# M0A21 register map
File version: 1.0
Registers are 32-bit, read-write, reset 0x0 unless marked. A register's access mark holds for its fields unless they carry their own. Offsets are from the block's base; [hi:lo] are bit positions; {n}, {i} and the like mark numbered series; 'fields as' and 'values as' point back to an identical list.

## ACMP01 — ACMP Register Map
Base 0x40045000
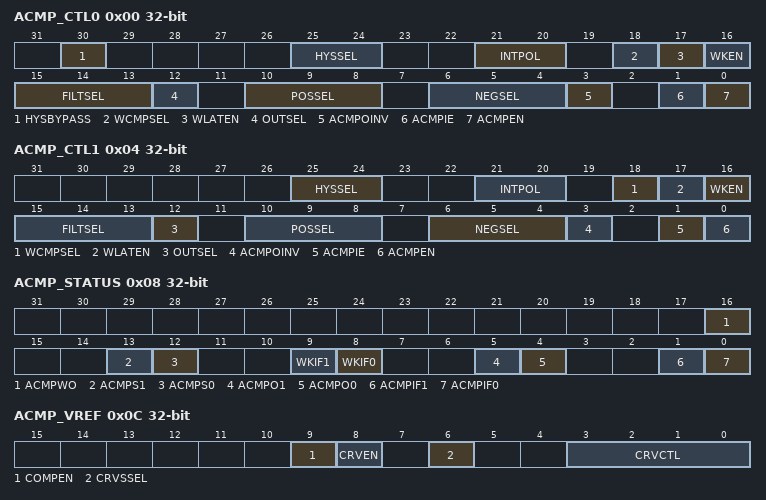
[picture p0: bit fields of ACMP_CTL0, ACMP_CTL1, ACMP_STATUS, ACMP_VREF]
0x00 ACMP_CTL0 — Analog Comparator 0 Control Register
  [30] HYSBYPASS — Hysteresis Adjust Function Selection
    0=Enable adjust function; 1=Bypass adjust function
  [25:24] HYSSEL — Hysteresis Mode Selection
    0=Hysteresis is 0mV; 3=Hysteresis is 30mV
  [21:20] INTPOL — Interrupt Condition Polarity Selection. ACMPIF0 will be set to 1 when comparator output edge condition is detected.
    0=Rising edge or falling edge; 1=Rising edge; 2=Falling edge
  [18] WCMPSEL — Window Compare Mode Selection
    0=Window Compare Mode Disabled; 1=Window Compare Mode Selected
  [17] WLATEN — Window Latch Mode Enable Bit
    0=Window Latch Mode Disabled; 1=Window Latch Mode Enabled
  [16] WKEN — Power-down Wake-up Enable Bit
    0=Wake-up function Disabled; 1=Wake-up function Enabled
  [15:13] FILTSEL — Comparator Output Filter Count Selection
    0=Filter function is Disabled; 1=ACMP0 output is sampled 1 consecutive PCLK; 2=ACMP0 output is sampled 2 consecutive PCLKs; 3=ACMP0 output is sampled 4 consecutive PCLKs; 4=ACMP0 output is sampled 8 consecutive PCLKs; 5=ACMP0 output is sampled 16 consecutive PCLKs; 6=ACMP0 output is sampled 32 consecutive PCLKs; 7=ACMP0 output is sampled 64 consecutive PCLKs
  [12] OUTSEL — Comparator Output Select
    0=Comparator 0 output to ACMP0_O pin is unfiltered comparator output; 1=Comparator 0 output to ACMP0_O pin is from filter output
  [10:8] POSSEL — Comparator Positive Input Selection
    0=All positive input disabled; 1=Input from ACMP0_P0; 2=Comparator Reference Voltage (CRV); 3=DAC0 output
  [6:4] NEGSEL — Comparator Negative Input Selection
    0=All negative input disbaled; {v}=ACMP0_N{v-1} (v=1..4); 5=Comparator Reference Voltage (CRV)
  [3] ACMPOINV — Comparator Output Inverse
    0=Comparator 0 output inverse Disabled; 1=Comparator 0 output inverse Enabled
  [1] ACMPIE — Comparator Interrupt Enable Bit
    0=Comparator 0 interrupt Disabled; 1=Comparator 0 interrupt Enabled. If WKEN (ACMP_CTL0[16]) is set to 1, the wake-up interrupt function will be enabled as well
  [0] ACMPEN — Comparator Enable Bit
    0=Comparator 0 Disabled; 1=Comparator 0 Enabled
0x04 ACMP_CTL1 — Analog Comparator 1 Control Register
  [25:24] HYSSEL — Hysteresis Mode Selection
    0=Hysteresis is 0mV; 3=Hysteresis is 30mV
  [21:20] INTPOL — Interrupt Condition Polarity Selection. ACMPIF0 will be set to 1 when comparator output edge condition is detected.
    0=Rising edge or falling edge; 1=Rising edge; 2=Falling edge
  [18] WCMPSEL — Window Compare Mode Selection
    values as ACMP_CTL0.WCMPSEL
  [17] WLATEN — Window Latch Mode Enable Bit
    0=Window Latch Mode Disabled; 1=Window Latch Mode Enabled
  [16] WKEN — Power-down Wakeup Enable Bit
    0=Wake-up function Disabled; 1=Wake-up function Enabled
  [15:13] FILTSEL — Comparator Output Filter Count Selection
    0=Filter function is Disabled; 1=ACMP1 output is sampled 1 consecutive PCLK; 2=ACMP1 output is sampled 2 consecutive PCLKs; 3=ACMP1 output is sampled 4 consecutive PCLKs; 4=ACMP1 output is sampled 8 consecutive PCLKs; 5=ACMP1 output is sampled 16 consecutive PCLKs; 6=ACMP1 output is sampled 32 consecutive PCLKs; 7=ACMP1 output is sampled 64 consecutive PCLKs
  [12] OUTSEL — Comparator Output Select
    0=Comparator 1 output to ACMP1_O pin is unfiltered comparator output; 1=Comparator 1 output to ACMP1_O pin is from filter output
  [10:8] POSSEL — Comparator Positive Input Selection
    0=All positive input disabled; 1=Input from ACMP1_P0; 2=Comparator Reference Voltage (CRV); 3=DAC0 output
  [6:4] NEGSEL — Comparator Negative Input Selection
    0=All negative input disbaled; {v}=ACMP1_N{v-1} (v=1..4); 5=Comparator Reference Voltage (CRV)
  [3] ACMPOINV — Comparator Output Inverse Control
    0=Comparator 1 output inverse Disabled; 1=Comparator 1 output inverse Enabled
  [1] ACMPIE — Comparator Interrupt Enable Bit
    0=Comparator 1 interrupt Disabled; 1=Comparator 1 interrupt Enabled. If WKEN (ACMP_CTL1[16]) is set to 1, the wake-up interrupt function will be enabled as well
  [0] ACMPEN — Comparator Enable Bit
    0=Comparator 1 Disabled; 1=Comparator 1 Enabled
0x08 ACMP_STATUS — Analog Comparator Status Register
  [16] ACMPWO — Comparator Window Output. This bit shows the output status of window compare mode
    0=The positive input voltage is outside the window; 1=The positive input voltage is in the window
  [13] ACMPS1 — Comparator 1 Status. Synchronized to the PCLK to allow reading by software. Cleared when the comparator 1 is disabled, i.e. ACMPEN (ACMP_CTL1[0]) is cleared to 0.
  [12] ACMPS0 — Comparator 0 Status. Synchronized to the PCLK to allow reading by software. Cleared when the comparator 0 is disabled, i.e. ACMPEN (ACMP_CTL0[0]) is cleared to 0.
  [9] WKIF1 — Comparator 1 Power-down Wake-up Interrupt Flag. This bit will be set to 1 when ACMP1 wake-up interrupt event occurs. Note: Write 1 to clear this bit to 0.
    0=No power-down wake-up occurred; 1=Power-down wake-up occurred
  [8] WKIF0 — Comparator 0 Power-down Wake-up Interrupt Flag. This bit will be set to 1 when ACMP0 wake-up interrupt event occurs. Note: Write 1 to clear this bit to 0.
    values as WKIF1
  [5] ACMPO1 — Comparator 1 Output. Synchronized to the PCLK to allow reading by software. Cleared when the comparator 1 is disabled, i.e. ACMPEN (ACMP_CTL1[0]) is cleared to 0.
  [4] ACMPO0 — Comparator 0 Output. Synchronized to the PCLK to allow reading by software. Cleared when the comparator 0 is disabled, i.e. ACMPEN (ACMP_CTL0[0]) is cleared to 0.
  [1] ACMPIF1 — Comparator 1 Interrupt Flag. This bit is set by hardware when the edge condition defined by INTPOL (ACMP_CTL1[21:20]) is detected on comparator 1 output. This will cause an interrupt if ACMPIE (ACMP_CTL1[1]) is set to 1. Note: Write 1 to clear this bit to 0.
  [0] ACMPIF0 — Comparator 0 Interrupt Flag. This bit is set by hardware when the edge condition defined by INTPOL (ACMP_CTL0[21:20]) is detected on comparator 0 output. This will generate an interrupt if ACMPIE (ACMP_CTL0[1]) is set to 1. Note: Write 1 to clear this bit to 0.
0x0C ACMP_VREF — Analog Comparator Reference Voltage Control Register
  [9] COMPEN — Comparator Bias Enable Bit
    0=Comparator bias Disabled; 1=Comparator bias Enabled
  [8] CRVEN — CRV Function Enable Bit
    0=CRV function Disabled; 1=CRV function Enabled
  [6] CRVSSEL — CRV Source Voltage Selection
    0=AVDD (voltage of VDD pin)is selected as CRV source voltage; 1=Internal VREF is selected as as CRV source voltage
  [3:0] CRVCTL — Comparator Reference Voltage Setting
